# nrf9230_enga_application register map
Vendor: Nordic Semiconductor; Series: nRF92; File version: 1
CPU: CM33 r0p4, little endian, MPU, FPU, 3 interrupt priority bits, 480 interrupts, 4 SAU regions
Registers are 32-bit, read-write, reset 0x0 unless marked. A register's access mark holds for its fields unless they carry their own. Offsets are from the block's base; [hi:lo] are bit positions; lines under a group give offsets from that group; {n}, {i} and the like mark numbered series.

## RESETINFO_S — RESETINFO
Base 0x5201E000; alternate view of LRCCONF010_S
0x4A0 RESETREAS group — Unspecified
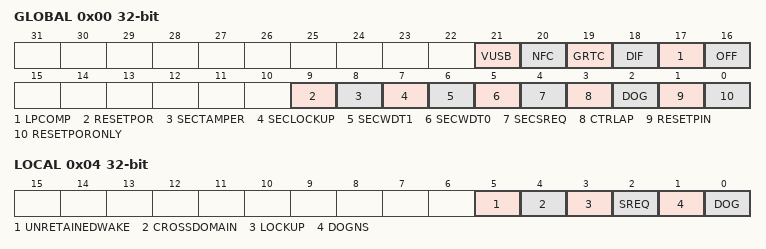
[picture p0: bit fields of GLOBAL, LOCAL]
  0x00 GLOBAL — Global reset reason.
    [all] fields
      0=NotDetected; 1=Detected
    [21] VUSB — Reset after wakeup from System OFF mode due to VBUS rising into valid range.
    [20] NFC — Reset due to wakeup from System OFF mode when wakeup is triggered by NFC field detection in sense mode.
    [19] GRTC — Reset due to wakeup from System OFF mode when wakeup is triggered by GRTC interrupt.
    [18] DIF — Reset due to wakeup from System OFF mode when wakeup is triggered by entering the debug interface mode.
    [17] LPCOMP — Reset due to wakeup from System OFF mode when wakeup is triggered by LPCOMP (Low Power Comparator).
    [16] OFF — Reset due to wakeup from System OFF mode when wakeup is triggered by DETECT signal from GPIO.
    [9] RESETPOR — Reset from power on reset (reset reason other than POR or BOR).
    [8] SECTAMPER — Reset due to secure domain tamper detected
    [7] SECLOCKUP — Reset due to secure domain lockup.
    [6] SECWDT1 — Reset due to the second instance of watchdog timer in secure domain detected.
    [5] SECWDT0 — Reset due to the first instance of watchdog timer in secure domain detected.
    [4] SECSREQ — Reset due to secure domain system reset request.
    [3] CTRLAP — Reset from CTRL-AP detected.
    [2] DOG — Reset from the SysCtrl watchdog timer detected.
    [1] RESETPIN — Reset from pin reset detected.
    [0] RESETPORONLY — Reset from power on reset (reset reason POR or BOR).
  0x04 LOCAL — Local reset reason.
    [5] UNRETAINEDWAKE — Reset due to wake from unretained state.
    [4] CROSSDOMAIN — Reset due to cross domain reset source.
      0=NotDetected; 1=Detected
    [3] LOCKUP — Reset from local CPU lockup detected
      0=NotDetected; 1=Detected
    [2] SREQ — Reset from the local soft reset request detected.
      0=NotDetected; 1=Detected
    [1] DOGNS — Reset from the local non-secure watchdog timer detected
      0=NotDetected; 1=Detected
    [0] DOG — Reset from the local watchdog timer detected
      0=NotDetected; 1=Detected
0x4A8 ERROR group — Unspecified
  0x00 STATUS — Reset error status.
    [3:0] ERRORSTATUS
  0x04 ADDRESS — Reset error address.
    [31:0] ERRORADDRESS
0x4C0 RESTOREVALID — Valid restore image is present in RAM.
  [0] RESTOREVALID
    0=NotPreset (Not present); 1=Present
0x4C4 MASKLOCKUP — Mask CPU lockup signal.
  [0] MASK — Mask lockup signal
    0=NotMask (Do not mask lockup signal); 1=Mask lockup signal

## SWI0_NS — Software interrupt 0
Base 0x42058000
Same registers: SWI1_NS 0x42059000, SWI2_NS 0x4205A000, SWI3_NS 0x4205B000, SWI4_NS 0x4205C000, SWI5_NS 0x4205D000, SWI6_NS 0x4205E000, SWI7_NS 0x4205F000

## BELLBOARD_NS — BELLBOARD APB registers 0
Base 0x4F09A000
Same registers: BELLBOARD_S 0x5F09A000
{0x0+4i} TASKS_TRIGGER[{i}] (i=0..31) wo — Description collection: Task TRIGGER[n]
  [0] TASKS_TRIGGER — Task TRIGGER[n]
    1=Trigger task
{0x100+4i} EVENTS_TRIGGERED[{i}] (i=0..31) — Description collection: Event TRIGGERED[n]
  [0] EVENTS_TRIGGERED — Event TRIGGERED[n]
    0=NotGenerated (Event not generated); 1=Generated (Event generated)
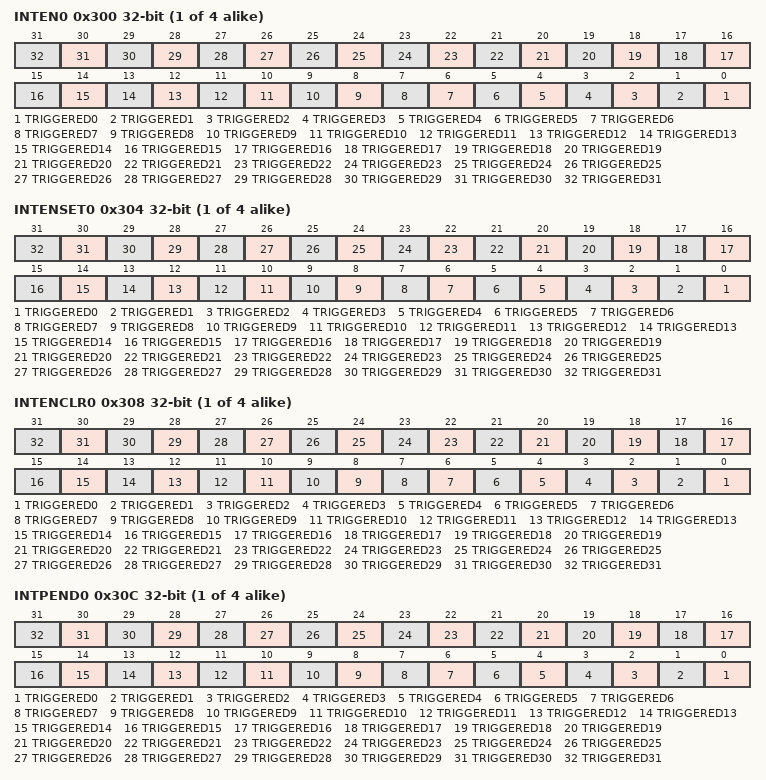
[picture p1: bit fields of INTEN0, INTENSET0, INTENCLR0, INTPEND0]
{0x300+0x10*i} INTEN{i} (i=0..3) — Enable or disable interrupt
  [all] fields
    0=Disabled; 1=Enabled
  [n] TRIGGERED{n} (n=0..31) — Enable or disable interrupt for event TRIGGERED[{n}]
{0x304+0x10*i} INTENSET{i} (i=0..3) — Enable interrupt
  [all] fields
    on read: 0=Disabled (Read: Disabled); 1=Enabled (Read: Enabled) | on write: 1=Set (Enable)
  [n] TRIGGERED{n} (n=0..31) — Write '1' to enable interrupt for event TRIGGERED[{n}]
{0x308+0x10*i} INTENCLR{i} (i=0..3) — Disable interrupt
  [all] fields
    on read: 0=Disabled (Read: Disabled); 1=Enabled (Read: Enabled) | on write: 1=Clear (Disable)
  [n] TRIGGERED{n} (n=0..31) — Write '1' to disable interrupt for event TRIGGERED[{n}]
{0x30C+0x10*i} INTPEND{i} ro (i=0..3) — Pending interrupts
  [all] fields
    on read: 0=NotPending (Read: Not pending); 1=Pending (Read: Pending)
  [n] TRIGGERED{n} (n=0..31) — Read pending status of interrupt for event TRIGGERED[{n}]
